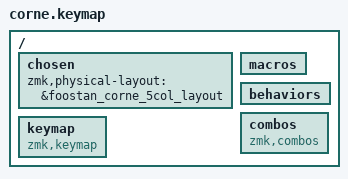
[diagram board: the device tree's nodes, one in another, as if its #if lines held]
#include <behaviors.dtsi>
#include <dt-bindings/zmk/keys.h>
#include <dt-bindings/zmk/bt.h>
#include <dt-bindings/zmk/ext_power.h>






#include "./CONFIG.h"


#include "./features/__BASE__/preprocessor_macros.c"


#include "./features/__BASE__/aliases_key_positions.dtsi"
#if defined NAQUADAH
    #include "./features/__BASE__/aliases_layers_NAQUADAH.dtsi"
#elif defined PROMETHIUM
    #include "./features/__BASE__/aliases_layers_PROMETHIUM.dtsi"
#elif defined RHODIUM
    #include "./features/__BASE__/aliases_layers_RHODIUM.dtsi"
#else
    #include "./features/__BASE__/aliases_layers.dtsi"
#endif

#include "./features/hands_down/aliases.dtsi"
#include "./features/hands_down/adaptive_keys/aliases.dtsi"



#include "./features/__BASE__/default_behaviors_config.dtsi"



/ {
    chosen {
        zmk,physical-layout = &foostan_corne_5col_layout;
    };



    macros {
        #include "./features/hands_down/macros.dtsi"
        #include "./features/hands_down/adaptive_keys/macros.dtsi"
        #include "./features/hands_down/mods/macros.dtsi"
        #include "./features/hands_down/h_digraphs/macros.dtsi"
        #include "./features/hands_down/pronouns/macros.dtsi"

        #include "./features/hands_down/zz__INVESTIGATE__zz/app_switcher/macros.dtsi"
        #include "./features/hands_down/zz__INVESTIGATE__zz/brackets/macros.dtsi"
        #include "./features/hands_down/zz__INVESTIGATE__zz/diacritic/macros.dtsi"

        #include "./features/switch_device/macros.dtsi"
    };



    behaviors {
        #include "./features/__EXPERIMENT__/behaviors.dtsi"

        #include "./features/hands_down/behaviors.dtsi"
        #include "./features/hands_down/adaptive_keys/behaviors.dtsi"
        #include "./features/hands_down/mods/behaviors.dtsi"
        #include "./features/hands_down/linger_keys/behaviors.dtsi"
        #include "./features/hands_down/mod_morph/behaviors.dtsi"

        #include "./features/hands_down/zz__INVESTIGATE__zz/app_switcher/behaviors.dtsi"

        #include "./features/switch_device/behaviors.dtsi"
    };



    combos {
        compatible = "zmk,combos";

        #include "./features/__EXPERIMENT__/combos.dtsi"

        // This file needs to be before the other combos files, to ensure the overrides are applied.
        #include "./features/hands_down/combos_linwin.dtsi"

        #include "./features/hands_down/combos.dtsi"
        #include "./features/hands_down/adaptive_keys/combos.dtsi"
        // #include "./features/hands_down/h_digraphs/combos.dtsi"
        // #include "./features/hands_down/pronouns/combos.dtsi"

        // #include "./features/hands_down/zz__INVESTIGATE__zz/diacritic/combos.dtsi"
        // #include "./features/hands_down/zz__INVESTIGATE__zz/selection/combos.dtsi"
    };



    keymap {
        compatible = "zmk,keymap";

        #if defined EXPERIMENT
            #include "./features/__EXPERIMENT__/EXPERIMENT_LAYER.dtsi"
        #else
            #if defined NAQUADAH
                #include "./features/hands_down/layers_A_NAQUADAH_alpha.dtsi"
                #include "./features/hands_down/layers_A_NAQUADAH_alpha_linwin.dtsi"
                #include "./features/hands_down/layers_B_NAQUADAH_adaptive_keys.dtsi"
            #elif defined PROMETHIUM
                #include "./features/hands_down/layers_A_PROMETHIUM_alpha.dtsi"
                #include "./features/hands_down/layers_A_PROMETHIUM_alpha_linwin.dtsi"
                #include "./features/hands_down/layers_B_PROMETHIUM_adaptive_keys.dtsi"
            #elif defined RHODIUM
                #include "./features/hands_down/layers_A_RHODIUM_alpha.dtsi"
                #include "./features/hands_down/layers_A_RHODIUM_alpha_linwin.dtsi"
                #include "./features/hands_down/layers_B_RHODIUM_adaptive_keys.dtsi"
            #else
                #include "./features/hands_down/layers_A_alpha.dtsi"
                #include "./features/hands_down/layers_A_alpha_linwin.dtsi"
                #include "./features/hands_down/layers_B_adaptive_keys.dtsi"
            #endif
            #include "./features/hands_down/layers_C_extra.dtsi"
            #include "./features/hands_down/layers_C_extra_linwin.dtsi"
        #endif
    };
};
